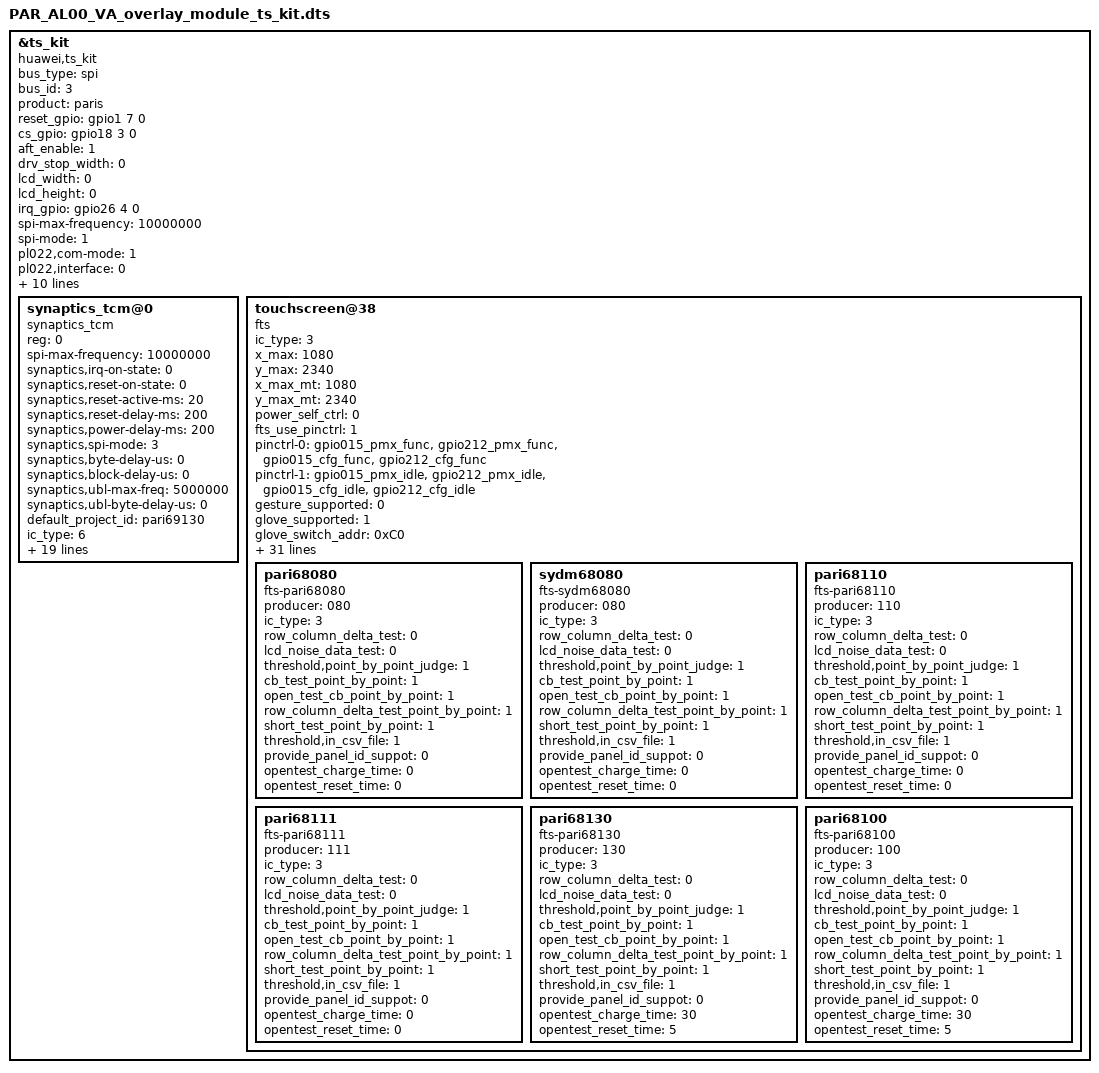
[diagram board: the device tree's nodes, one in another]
/*touch_panel*/
	&ts_kit {
		compatible = "huawei,ts_kit";
		bus_type = "spi";
		bus_id = <3>;
		product = "paris";
		reset_gpio = <&gpio1 7 0>;
		cs_gpio = <&gpio18 3 0>;
		aft_enable = <1>;
		drv_stop_width = <0>;
		lcd_width = <0>;
		lcd_height = <0>;
		irq_gpio = <&gpio26 4 0>;
		spi-max-frequency = <10000000>;
		spi-mode = <1>;
		pl022,com-mode = <1>;
		pl022,interface = <0>;
		pl022,rx-level-trig = <3>;
		pl022,tx-level-trig = <3>;
		pl022,ctrl-len = <7>;
		pl022,wait-state = <0>;
		pl022,duplex = <0>;
		pl022,slave-tx-disable = <0>;
		cs_reset_low_delay = <10>;
		cs_reset_high_delay = <200>;
		hide_plain_id = <1>;
		touch_switch_need_process = <1>;
		synaptics_tcm@0 {
			compatible = "synaptics_tcm";
			reg = <0>;
			spi-max-frequency = <10000000>;
			synaptics,irq-on-state = <0>;
			synaptics,reset-on-state = <0>;
			synaptics,reset-active-ms = <20>;
			synaptics,reset-delay-ms = <200>;
			synaptics,power-delay-ms = <200>;
			synaptics,spi-mode = <3>;
			synaptics,byte-delay-us = <0>;
			synaptics,block-delay-us = <0>;
			synaptics,ubl-max-freq = <5000000>;
			synaptics,ubl-byte-delay-us = <0>;
			default_project_id = "pari69130";
			ic_type = <6>;
			irq_config = <0>;
			vci_gpio_type = <0>;
			vci_regulator_type = <0>;
			vddio_gpio_type = <0>;
			vddio_regulator_type = <0>;
			use_old_projectid = <1>;
			x_max = <1080>;
			y_max = <2340>;
			x_max_mt = <1080>;
			y_max_mt = <2340>;
			max_finger_objects = <10>;
			rawdata_newformatflag = <1>;
			roi_supported = <1>;
			glove_supported = <1>;
			charger_supported = <1>;
			aft_wxy_enable = <1>;
			touch_switch_flag = <4>; // 1-doze 2-game 4-scene
			use_dma_download_firmware = <1>;
			downmload_firmware_frequency = <8000000>;
		};
		touchscreen@38 {
			compatible = "fts";
			ic_type = <3>;
			x_max = <1080>;
			y_max = <2340>;
			x_max_mt = <1080>;
			y_max_mt = <2340>;
			power_self_ctrl = <0>; /*0-Power is controlled by LCD, 1-Power is self controlled*/
			fts_use_pinctrl = <1>;
			pinctrl-names = "default", "idle";
			pinctrl-0 = <&gpio015_pmx_func &gpio212_pmx_func &gpio015_cfg_func &gpio212_cfg_func>;
			pinctrl-1 = <&gpio015_pmx_idle &gpio212_pmx_idle &gpio015_cfg_idle &gpio212_cfg_idle>;
			gesture_supported = <0>;
			glove_supported = <1>;
			glove_switch_addr = <0xC0>;
			roi_supported = <1>;
			roi_switch_addr = <0x9B>;
			vci_value;
			vddio_value;
			vci_gpio_type = <0>;
			vci_regulator_type = <0>;
			vddio_gpio_type = <0>;
			vddio_regulator_type = <0>;
			slave_address = <0x38>;
			reset_self_ctrl = <1>;
			chip_id = <0x87>;
			upgrade_loop_times = <5>;
			fts-vdd-supply;
			fts-io-supply;
			irq_config = <3>;
			algo_id = <1>;
			is_in_cell = <1>;
			need_wd_check_status = <1>;
			support_get_tp_color = <1>;
			only_open_once_captest_threshold = <1>;
			projectid_length_control_flag = <1>;
			enable_edge_touch = <1>;
			aft_wxy_enable = <1>;
			use_lcdkit_power_notify = <1>;
			rawdata_newformatflag = <1>;
			fw_update_duration_check = <300>;
			touch_switch_flag = <4>; // 1-doze 2-game 4-scene
			touch_switch_scene_reg = <0xC3>;
			read_debug_reg_and_differ = <1>;
			palm_iron_support = <1>;
			use_dma_download_firmware = <1>;
			pari68080{
				producer = "080";
				ic_type = <3>;
				compatible = "fts-pari68080";
				row_column_delta_test = <0>;
				lcd_noise_data_test = <0>;
				threshold,point_by_point_judge = <1>;
				cb_test_point_by_point = <1>;
				open_test_cb_point_by_point = <1>;
				row_column_delta_test_point_by_point = <1>;
				short_test_point_by_point = <1>;
				threshold,in_csv_file = <1>;
				provide_panel_id_suppot = <0>;
				opentest_charge_time = <0>;
				opentest_reset_time = <0>;
			};
			sydm68080{
				producer = "080";
				ic_type = <3>;
				compatible = "fts-sydm68080";
				row_column_delta_test = <0>;
				lcd_noise_data_test = <0>;
				threshold,point_by_point_judge = <1>;
				cb_test_point_by_point = <1>;
				open_test_cb_point_by_point = <1>;
				row_column_delta_test_point_by_point = <1>;
				short_test_point_by_point = <1>;
				threshold,in_csv_file = <1>;
				provide_panel_id_suppot = <0>;
				opentest_charge_time = <0>;
				opentest_reset_time = <0>;
			};
			pari68110{
				producer = "110";
				ic_type = <3>;
				compatible = "fts-pari68110";
				row_column_delta_test = <0>;
				lcd_noise_data_test = <0>;
				threshold,point_by_point_judge = <1>;
				cb_test_point_by_point = <1>;
				open_test_cb_point_by_point = <1>;
				row_column_delta_test_point_by_point = <1>;
				short_test_point_by_point = <1>;
				threshold,in_csv_file = <1>;
				provide_panel_id_suppot = <0>;
				opentest_charge_time = <0>;
				opentest_reset_time = <0>;
			};
			pari68111{
				producer = "111";
				ic_type = <3>;
				compatible = "fts-pari68111";
				row_column_delta_test = <0>;
				lcd_noise_data_test = <0>;
				threshold,point_by_point_judge = <1>;
				cb_test_point_by_point = <1>;
				open_test_cb_point_by_point = <1>;
				row_column_delta_test_point_by_point = <1>;
				short_test_point_by_point = <1>;
				threshold,in_csv_file = <1>;
				provide_panel_id_suppot = <0>;
				opentest_charge_time = <0>;
				opentest_reset_time = <0>;
			};
			pari68130{
				producer = "130";
				ic_type = <3>;
				compatible = "fts-pari68130";
				row_column_delta_test = <0>;
				lcd_noise_data_test = <0>;
				threshold,point_by_point_judge = <1>;
				cb_test_point_by_point = <1>;
				open_test_cb_point_by_point = <1>;
				row_column_delta_test_point_by_point = <1>;
				short_test_point_by_point = <1>;
				threshold,in_csv_file = <1>;
				provide_panel_id_suppot = <0>;
				opentest_charge_time = <30>;
				opentest_reset_time = <5>;
			};
			pari68100{
				producer = "100";
				ic_type = <3>;
				compatible = "fts-pari68100";
				row_column_delta_test = <0>;
				lcd_noise_data_test = <0>;
				threshold,point_by_point_judge = <1>;
				cb_test_point_by_point = <1>;
				open_test_cb_point_by_point = <1>;
				row_column_delta_test_point_by_point = <1>;
				short_test_point_by_point = <1>;
				threshold,in_csv_file = <1>;
				provide_panel_id_suppot = <0>;
				opentest_charge_time = <30>;
				opentest_reset_time = <5>;
			};
		};

	};
